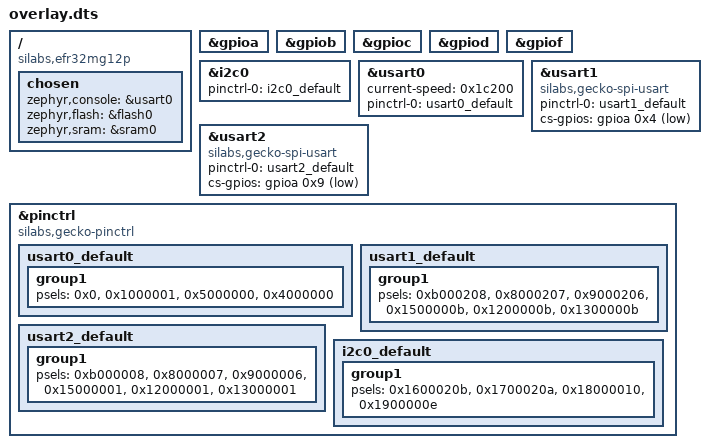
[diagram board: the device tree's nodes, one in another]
/ {
	compatible = "silabs,efr32mg12p", "silabs,slwrb4161a";
	chosen {
		zephyr,console = &usart0;
		zephyr,flash = &flash0;
		zephyr,sram = &sram0;
	};
};
&gpioa{
	status = "okay";
};
&gpiob{
	status = "okay";
};
&gpioc{
	status = "okay";
};
&gpiod{
	status = "okay";
};
&gpiof{
	status = "okay";
};
&i2c0{
	status = "okay";
	pinctrl-0 = < &i2c0_default >;
	pinctrl-names = "default";
};
&usart0{
	status = "okay";
	current-speed = < 0x1c200 >;
	pinctrl-0 = < &usart0_default >;
	pinctrl-names = "default";
};
&usart1{
	compatible = "silabs,gecko-spi-usart";
	status = "okay";
	#address-cells = < 0x1 >;
	#size-cells = < 0x0 >;
	pinctrl-0 = < &usart1_default >;
	pinctrl-names = "default";
	cs-gpios = < &gpioa 0x4 0x1 >;
};
&usart2{
	compatible = "silabs,gecko-spi-usart";
	status = "okay";
	#address-cells = < 0x1 >;
	#size-cells = < 0x0 >;
	pinctrl-0 = < &usart2_default >;
	pinctrl-names = "default";
	cs-gpios = < &gpioa 0x9 0x1 >;
};
&pinctrl{
	compatible = "silabs,gecko-pinctrl";
	usart0_default: usart0_default {
		group1 {
			psels = < 0x0 >, < 0x1000001 >, < 0x5000000 >, < 0x4000000 >;
		};
	};
	usart1_default: usart1_default {
		group1 {
			psels = < 0xb000208 >, < 0x8000207 >, < 0x9000206 >, < 0x1500000b >, < 0x1200000b >, < 0x1300000b >;
		};
	};
	usart2_default: usart2_default {
		group1 {
			psels = < 0xb000008 >, < 0x8000007 >, < 0x9000006 >, < 0x15000001 >, < 0x12000001 >, < 0x13000001 >;
		};
	};
	i2c0_default: i2c0_default {
		group1 {
			psels = < 0x1600020b >, < 0x1700020a >, < 0x18000010 >, < 0x1900000e >;
		};
	};
};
